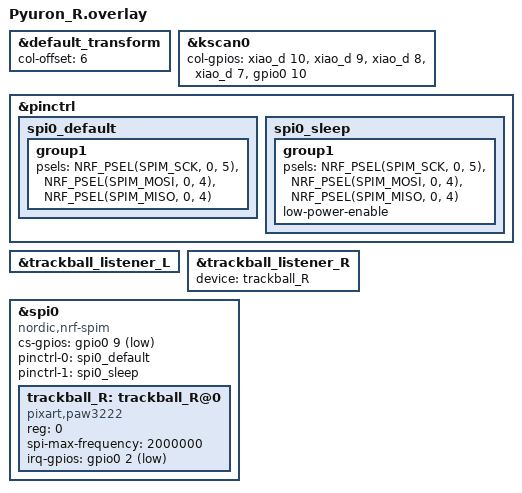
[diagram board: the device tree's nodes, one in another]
#include <zephyr/dt-bindings/input/input-event-codes.h>
#include "Pyuron.dtsi"

&default_transform {
    col-offset = <6>;
};

&kscan0 {
    col-gpios = <&xiao_d 10 GPIO_ACTIVE_HIGH>,
                <&xiao_d 9 GPIO_ACTIVE_HIGH>,
                <&xiao_d 8 GPIO_ACTIVE_HIGH>,
                <&xiao_d 7 GPIO_ACTIVE_HIGH>,
                <&gpio0 10 GPIO_ACTIVE_HIGH>;
};

&pinctrl {
    spi0_default: spi0_default {
        group1 {
            psels = <NRF_PSEL(SPIM_SCK, 0, 5)>,
                    <NRF_PSEL(SPIM_MOSI, 0, 4)>,
                    <NRF_PSEL(SPIM_MISO, 0, 4)>;
        };
    };

    spi0_sleep: spi0_sleep {
        group1 {
            psels = <NRF_PSEL(SPIM_SCK, 0, 5)>,
                    <NRF_PSEL(SPIM_MOSI, 0, 4)>,
                    <NRF_PSEL(SPIM_MISO, 0, 4)>;
            low-power-enable;
        };
    };
};

&trackball_listener_L {
    status = "okay";
};

&trackball_listener_R {
    status = "okay";
    device = <&trackball_R>;
};

&spi0 {
    status = "okay";
    cs-gpios = <&gpio0 9 GPIO_ACTIVE_LOW>;
    pinctrl-0 = <&spi0_default>;
    pinctrl-1 = <&spi0_sleep>;
    pinctrl-names = "default", "sleep";
    compatible = "nordic,nrf-spim";

    trackball_R: trackball_R@0 {
        status = "okay";
        compatible = "pixart,paw3222";
        reg = <0>;
        spi-max-frequency = <2000000>;
        irq-gpios = <&gpio0 2 (GPIO_ACTIVE_LOW | GPIO_PULL_UP)>;
    };
};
